# CY8C5287AXI_LP095 register map
File version: 0.1
Registers are 8-bit, read-write, no defined reset value unless marked. A register's access mark holds for its fields unless they carry their own. Offsets are from the block's base; [hi:lo] are bit positions; {n}, {i} and the like mark numbered series; 'fields as' and 'values as' point back to an identical list.

## PWM_DDIM_2
Base 0x00000000
0x40006420 PWM_DDIM_2_COMPARE_1 16-bit — UDB.D0 - Assigned Compare1 Value
0x40006430 PWM_DDIM_2_COMPARE_2 16-bit — UDB.D1 - Assigned Compare2 Value
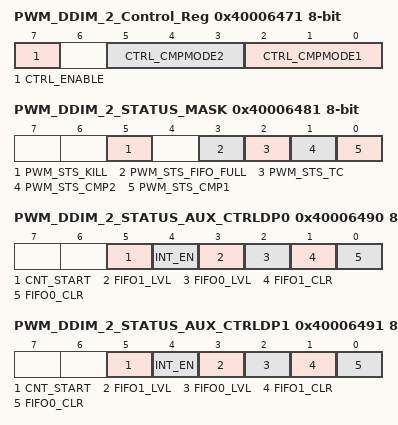
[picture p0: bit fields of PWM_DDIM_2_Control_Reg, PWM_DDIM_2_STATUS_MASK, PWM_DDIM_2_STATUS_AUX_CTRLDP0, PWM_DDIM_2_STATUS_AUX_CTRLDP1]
0x40006471 PWM_DDIM_2_Control_Reg — UDB Control Register - Assigned Control Register Value
  [7] CTRL_ENABLE — Enable the PWM
  [5:3] CTRL_CMPMODE2 — Compare mode 2
  [2:0] CTRL_CMPMODE1 — Compare mode 1
0x40006481 PWM_DDIM_2_STATUS_MASK — UDB Status bits Interrupt Mask Enable Register
  [5] PWM_STS_KILL ro — Enables the Interrupt on Kill
  [3] PWM_STS_FIFO_FULL ro — FIFO Full Status Mask
  [2] PWM_STS_TC ro — Enables the Interrupt on Terminal Count
  [1] PWM_STS_CMP2 ro — Enables the Interrupt on Compare 2
  [0] PWM_STS_CMP1 ro — Enables the Interrupt on Compare 1
0x40006490 PWM_DDIM_2_STATUS_AUX_CTRLDP0 — UDB Auxilliary Control Register
  [5] CNT_START — FIFO0 clear
    0=E_CNT_START0 (Disable counter); 1=E_CNT_START1 (Enable counter)
  [4] INT_EN
    0=E_INT_EN0 (Interrupt disabled); 1=E_INT_EN1 (Interrupt enabled)
  [3] FIFO1_LVL — FIFO level
    0=E_FIFO_LVL_0 (FIFO LVL: input mode: FIFO not full; output mode: FIFO not empty); 1=E_FIFO_LVL_1 (FIFO LVL: input mode: FIFO at least 1/2 empty; output mode: FIFO at least 1/2 full)
  [2] FIFO0_LVL — FIFO level
    values as FIFO1_LVL
  [1] FIFO1_CLR — FIFO1 clear
    0=E_FIFO_CLR_0 (Normal FIFO operation); 1=E_FIFO_CLR_1 (Clear FIFO state)
  [0] FIFO0_CLR — FIFO0 clear
    values as FIFO1_CLR
0x40006491 PWM_DDIM_2_STATUS_AUX_CTRLDP1 — UDB Auxilliary Control Register
  fields as PWM_DDIM_2_STATUS_AUX_CTRLDP0

## PWM_ADIM_2
Base 0x00000000
0x40006428 PWM_ADIM_2_COMPARE_1 16-bit — UDB.D0 - Assigned Compare1 Value
0x40006438 PWM_ADIM_2_COMPARE_2 16-bit — UDB.D1 - Assigned Compare2 Value
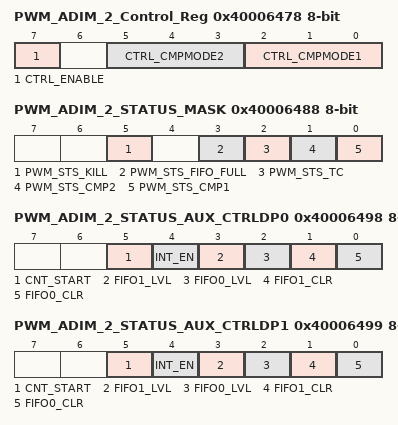
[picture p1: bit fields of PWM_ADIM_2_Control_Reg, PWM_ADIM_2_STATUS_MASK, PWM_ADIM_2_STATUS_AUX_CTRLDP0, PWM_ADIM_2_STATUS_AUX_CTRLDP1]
0x40006478 PWM_ADIM_2_Control_Reg — UDB Control Register - Assigned Control Register Value
  [7] CTRL_ENABLE — Enable the PWM
  [5:3] CTRL_CMPMODE2 — Compare mode 2
  [2:0] CTRL_CMPMODE1 — Compare mode 1
0x40006488 PWM_ADIM_2_STATUS_MASK — UDB Status bits Interrupt Mask Enable Register
  [5] PWM_STS_KILL ro — Enables the Interrupt on Kill
  [3] PWM_STS_FIFO_FULL ro — FIFO Full Status Mask
  [2] PWM_STS_TC ro — Enables the Interrupt on Terminal Count
  [1] PWM_STS_CMP2 ro — Enables the Interrupt on Compare 2
  [0] PWM_STS_CMP1 ro — Enables the Interrupt on Compare 1
0x40006498 PWM_ADIM_2_STATUS_AUX_CTRLDP0 — UDB Auxilliary Control Register
  [5] CNT_START — FIFO0 clear
    0=E_CNT_START0 (Disable counter); 1=E_CNT_START1 (Enable counter)
  [4] INT_EN
    0=E_INT_EN0 (Interrupt disabled); 1=E_INT_EN1 (Interrupt enabled)
  [3] FIFO1_LVL — FIFO level
    0=E_FIFO_LVL_0 (FIFO LVL: input mode: FIFO not full; output mode: FIFO not empty); 1=E_FIFO_LVL_1 (FIFO LVL: input mode: FIFO at least 1/2 empty; output mode: FIFO at least 1/2 full)
  [2] FIFO0_LVL — FIFO level
    values as FIFO1_LVL
  [1] FIFO1_CLR — FIFO1 clear
    0=E_FIFO_CLR_0 (Normal FIFO operation); 1=E_FIFO_CLR_1 (Clear FIFO state)
  [0] FIFO0_CLR — FIFO0 clear
    values as FIFO1_CLR
0x40006499 PWM_ADIM_2_STATUS_AUX_CTRLDP1 — UDB Auxilliary Control Register
  fields as PWM_ADIM_2_STATUS_AUX_CTRLDP0

## PWM_BOTHDIM6
Base 0x00000000
0x40006422 PWM_BOTHDIM6_COMPARE_1 16-bit — UDB.D0 - Assigned Compare1 Value
0x40006432 PWM_BOTHDIM6_COMPARE_2 16-bit — UDB.D1 - Assigned Compare2 Value
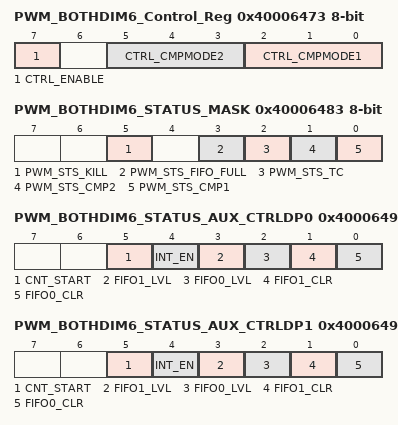
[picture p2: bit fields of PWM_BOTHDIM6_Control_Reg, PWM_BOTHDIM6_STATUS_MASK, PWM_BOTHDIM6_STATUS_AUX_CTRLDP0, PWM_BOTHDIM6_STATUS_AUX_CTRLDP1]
0x40006473 PWM_BOTHDIM6_Control_Reg — UDB Control Register - Assigned Control Register Value
  [7] CTRL_ENABLE — Enable the PWM
  [5:3] CTRL_CMPMODE2 — Compare mode 2
  [2:0] CTRL_CMPMODE1 — Compare mode 1
0x40006483 PWM_BOTHDIM6_STATUS_MASK — UDB Status bits Interrupt Mask Enable Register
  [5] PWM_STS_KILL ro — Enables the Interrupt on Kill
  [3] PWM_STS_FIFO_FULL ro — FIFO Full Status Mask
  [2] PWM_STS_TC ro — Enables the Interrupt on Terminal Count
  [1] PWM_STS_CMP2 ro — Enables the Interrupt on Compare 2
  [0] PWM_STS_CMP1 ro — Enables the Interrupt on Compare 1
0x40006492 PWM_BOTHDIM6_STATUS_AUX_CTRLDP0 — UDB Auxilliary Control Register
  [5] CNT_START — FIFO0 clear
    0=E_CNT_START0 (Disable counter); 1=E_CNT_START1 (Enable counter)
  [4] INT_EN
    0=E_INT_EN0 (Interrupt disabled); 1=E_INT_EN1 (Interrupt enabled)
  [3] FIFO1_LVL — FIFO level
    0=E_FIFO_LVL_0 (FIFO LVL: input mode: FIFO not full; output mode: FIFO not empty); 1=E_FIFO_LVL_1 (FIFO LVL: input mode: FIFO at least 1/2 empty; output mode: FIFO at least 1/2 full)
  [2] FIFO0_LVL — FIFO level
    values as FIFO1_LVL
  [1] FIFO1_CLR — FIFO1 clear
    0=E_FIFO_CLR_0 (Normal FIFO operation); 1=E_FIFO_CLR_1 (Clear FIFO state)
  [0] FIFO0_CLR — FIFO0 clear
    values as FIFO1_CLR
0x40006493 PWM_BOTHDIM6_STATUS_AUX_CTRLDP1 — UDB Auxilliary Control Register
  fields as PWM_BOTHDIM6_STATUS_AUX_CTRLDP0

## PWM_BOTHDIM5
Base 0x00000000
0x40006426 PWM_BOTHDIM5_COMPARE_1 16-bit — UDB.D0 - Assigned Compare1 Value
0x40006436 PWM_BOTHDIM5_COMPARE_2 16-bit — UDB.D1 - Assigned Compare2 Value
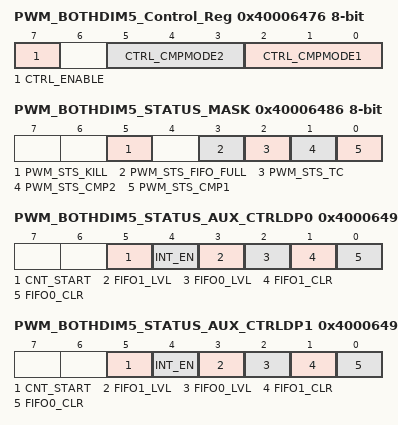
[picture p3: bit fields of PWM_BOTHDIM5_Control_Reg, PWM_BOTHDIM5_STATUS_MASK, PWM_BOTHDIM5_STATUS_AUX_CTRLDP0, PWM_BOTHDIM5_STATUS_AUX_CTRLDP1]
0x40006476 PWM_BOTHDIM5_Control_Reg — UDB Control Register - Assigned Control Register Value
  [7] CTRL_ENABLE — Enable the PWM
  [5:3] CTRL_CMPMODE2 — Compare mode 2
  [2:0] CTRL_CMPMODE1 — Compare mode 1
0x40006486 PWM_BOTHDIM5_STATUS_MASK — UDB Status bits Interrupt Mask Enable Register
  [5] PWM_STS_KILL ro — Enables the Interrupt on Kill
  [3] PWM_STS_FIFO_FULL ro — FIFO Full Status Mask
  [2] PWM_STS_TC ro — Enables the Interrupt on Terminal Count
  [1] PWM_STS_CMP2 ro — Enables the Interrupt on Compare 2
  [0] PWM_STS_CMP1 ro — Enables the Interrupt on Compare 1
0x40006496 PWM_BOTHDIM5_STATUS_AUX_CTRLDP0 — UDB Auxilliary Control Register
  [5] CNT_START — FIFO0 clear
    0=E_CNT_START0 (Disable counter); 1=E_CNT_START1 (Enable counter)
  [4] INT_EN
    0=E_INT_EN0 (Interrupt disabled); 1=E_INT_EN1 (Interrupt enabled)
  [3] FIFO1_LVL — FIFO level
    0=E_FIFO_LVL_0 (FIFO LVL: input mode: FIFO not full; output mode: FIFO not empty); 1=E_FIFO_LVL_1 (FIFO LVL: input mode: FIFO at least 1/2 empty; output mode: FIFO at least 1/2 full)
  [2] FIFO0_LVL — FIFO level
    values as FIFO1_LVL
  [1] FIFO1_CLR — FIFO1 clear
    0=E_FIFO_CLR_0 (Normal FIFO operation); 1=E_FIFO_CLR_1 (Clear FIFO state)
  [0] FIFO0_CLR — FIFO0 clear
    values as FIFO1_CLR
0x40006497 PWM_BOTHDIM5_STATUS_AUX_CTRLDP1 — UDB Auxilliary Control Register
  fields as PWM_BOTHDIM5_STATUS_AUX_CTRLDP0

## DMX_Control_Reg
Base 0x40006576
0x00 DMX_Control_Reg_CONTROL_REG

## ADC — SAR ADC
Base 0x00000000
0x40004614 SAR_TR0 — SAR trim register
{0x40005900+i} SAR_CSR{i} (i=0..6) — SAR status and control register {i}
0x40005B20 SAR_SW0 — SAR Analog Routing Register 0
{0x40005B20+i} SAR_SW{i} (i=2..4) — SAR Analog Routing Register {i}
0x40005B26 SAR_SW6 — SAR Analog Routing Register 6
0x40005B27 SAR_CLK — SAR Clock Selection Register
0x40005BA0 SAR_WRK 16-bit — SAR working register
